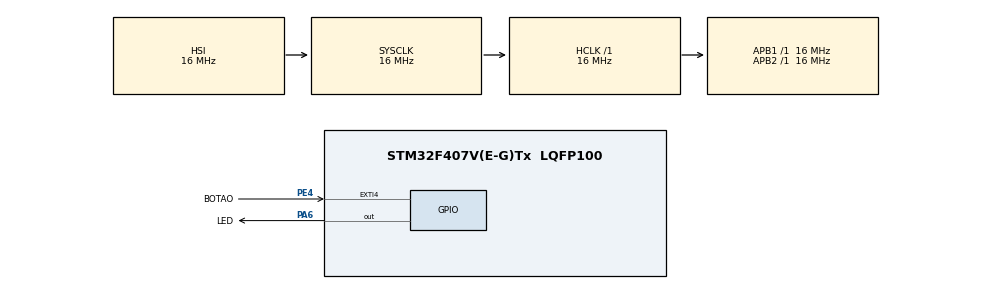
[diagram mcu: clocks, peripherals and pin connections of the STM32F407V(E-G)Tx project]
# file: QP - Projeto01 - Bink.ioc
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Mcu.Family=STM32F4
Mcu.Name=STM32F407V(E-G)Tx
Mcu.Package=LQFP100
NVIC.EXTI4_IRQn=true\:0\:0\:false\:false\:true\:true\:true\:true
NVIC.PriorityGroup=NVIC_PRIORITYGROUP_4
PA13.Mode=Serial_Wire
PA13.Signal=SYS_JTMS-SWDIO
PA14.Mode=Serial_Wire
PA14.Signal=SYS_JTCK-SWCLK
PA6.GPIO_Label=LED
PA6.Signal=GPIO_Output
PE4.GPIO_Label=BOTAO
PE4.GPIO_PuPd=GPIO_PULLUP
PE4.Signal=GPXTI4
ProjectManager.HeapSize=0x200
ProjectManager.StackSize=0x400
ProjectManager.TargetToolchain=STM32CubeIDE
RCC.AHBFreq_Value=16000000
RCC.APB1Freq_Value=16000000
RCC.APB2Freq_Value=16000000
RCC.CortexFreq_Value=16000000
RCC.HSE_VALUE=25000000
RCC.HSI_VALUE=16000000
RCC.LSE_VALUE=32768
RCC.SYSCLKFreq_VALUE=16000000
RCC.VCOOutputFreq_Value=192000000
board=custom

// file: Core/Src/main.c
/* USER CODE BEGIN Header */
/**
  ******************************************************************************
  * @file           : main.c
  * @brief          : Main program body
  ******************************************************************************
  * @attention
  *
  * Copyright (c) 2022 STMicroelectronics.
  * All rights reserved.
  *
  * This software is licensed under terms that can be found in the LICENSE file
  * in the root directory of this software component.
  * If no LICENSE file comes with this software, it is provided AS-IS.
  *
  ******************************************************************************
  */
/* USER CODE END Header */
#include "main.h"

/* USER CODE BEGIN Includes */

#include "qpc.h"

#include "SMLed.h"
#include "SMConsumer.h"

/* USER CODE END Includes */

/* USER CODE BEGIN PM */

Q_DEFINE_THIS_FILE

/* USER CODE END PM */

void SystemClock_Config(void);
static void MX_GPIO_Init(void);

int main(void)
{
  /* USER CODE BEGIN 1 */

	static QEvt const *evtQueueLed[10];
	static QEvt const *evtQueueConsumer[10];

	static QSubscrList l_subscrSto[MAX_PUB_SIG]; // Lista de inscritos do mecanismo publish-subscribe do QP.

	// Construtores dos Active Objects.
	SMLed_ctor();

  /* USER CODE END 1 */

  /* MCU Configuration--------------------------------------------------------*/

  /* Reset of all peripherals, Initializes the Flash interface and the Systick. */
  HAL_Init();

  /* Configure the system clock */
  SystemClock_Config();

  /* Initialize all configured peripherals */
  MX_GPIO_Init();
  /* USER CODE BEGIN 2 */

  // Inicializa o framework do QP.
  QF_init();

  QF_psInit(l_subscrSto, Q_DIM(l_subscrSto));

  uint8_t priority = 1;

  SMConsumer_ctor();

  QACTIVE_START(AO_SMLed, priority++, evtQueueLed, Q_DIM(evtQueueLed),(void *)0, 0U, (QEvt *)0);
  QACTIVE_START(AO_SMConsumer, priority++, evtQueueConsumer, Q_DIM(evtQueueConsumer), (void* )0, 0U, (QEvt* )0);

  // Executa a aplicação QF.
  return QF_run();

  /* USER CODE END 2 */

  /* Infinite loop */
  while (1)
  {

  }
}

void SystemClock_Config(void)
{
  RCC_OscInitTypeDef RCC_OscInitStruct = {0};
  RCC_ClkInitTypeDef RCC_ClkInitStruct = {0};

  /** Configure the main internal regulator output voltage
  */
  __HAL_RCC_PWR_CLK_ENABLE();
  __HAL_PWR_VOLTAGESCALING_CONFIG(PWR_REGULATOR_VOLTAGE_SCALE1);

  /** Initializes the RCC Oscillators according to the specified parameters
  * in the RCC_OscInitTypeDef structure.
  */
  RCC_OscInitStruct.OscillatorType = RCC_OSCILLATORTYPE_HSI;
  RCC_OscInitStruct.HSIState = RCC_HSI_ON;
  RCC_OscInitStruct.HSICalibrationValue = RCC_HSICALIBRATION_DEFAULT;
  RCC_OscInitStruct.PLL.PLLState = RCC_PLL_NONE;
  if (HAL_RCC_OscConfig(&RCC_OscInitStruct) != HAL_OK)
  {
    Error_Handler();
  }

  /** Initializes the CPU, AHB and APB buses clocks
  */
  RCC_ClkInitStruct.ClockType = RCC_CLOCKTYPE_HCLK|RCC_CLOCKTYPE_SYSCLK
                              |RCC_CLOCKTYPE_PCLK1|RCC_CLOCKTYPE_PCLK2;
  RCC_ClkInitStruct.SYSCLKSource = RCC_SYSCLKSOURCE_HSI;
  RCC_ClkInitStruct.AHBCLKDivider = RCC_SYSCLK_DIV1;
  RCC_ClkInitStruct.APB1CLKDivider = RCC_HCLK_DIV1;
  RCC_ClkInitStruct.APB2CLKDivider = RCC_HCLK_DIV1;

  if (HAL_RCC_ClockConfig(&RCC_ClkInitStruct, FLASH_LATENCY_0) != HAL_OK)
  {
    Error_Handler();
  }
}

static void MX_GPIO_Init(void)
{
  GPIO_InitTypeDef GPIO_InitStruct = {0};

  /* GPIO Ports Clock Enable */
  __HAL_RCC_GPIOE_CLK_ENABLE();
  __HAL_RCC_GPIOA_CLK_ENABLE();

  /*Configure GPIO pin Output Level */
  HAL_GPIO_WritePin(LED_GPIO_Port, LED_Pin, GPIO_PIN_RESET);

  /*Configure GPIO pin : BOTAO_Pin */
  GPIO_InitStruct.Pin = BOTAO_Pin;
  GPIO_InitStruct.Mode = GPIO_MODE_IT_RISING;
  GPIO_InitStruct.Pull = GPIO_PULLUP;
  HAL_GPIO_Init(BOTAO_GPIO_Port, &GPIO_InitStruct);

  /*Configure GPIO pin : LED_Pin */
  GPIO_InitStruct.Pin = LED_Pin;
  GPIO_InitStruct.Mode = GPIO_MODE_OUTPUT_PP;
  GPIO_InitStruct.Pull = GPIO_NOPULL;
  GPIO_InitStruct.Speed = GPIO_SPEED_FREQ_LOW;
  HAL_GPIO_Init(LED_GPIO_Port, &GPIO_InitStruct);

  /* EXTI interrupt init*/
  HAL_NVIC_SetPriority(EXTI4_IRQn, 0, 0);
  HAL_NVIC_EnableIRQ(EXTI4_IRQn);

}

/* USER CODE BEGIN 4 */

void QF_onStartup(void)
{
	SysTick_Config(SystemCoreClock * SYSTICK_INT_FREQ);
	NVIC_SetPriority(SysTick_IRQn, SysTick_PRIO);
}

void QF_onCleanup(void){}

void QV_onIdle(void)
{
	QF_INT_ENABLE();
}

void Q_onAssert(char_t const * const module, int_t location)
{
	QF_INT_DISABLE(); /* make sure that all interrupts are disabled */
	NVIC_SystemReset();
}

/* USER CODE END 4 */

void Error_Handler(void)
{
  __disable_irq();
  while (1)
  {
  }
}
